VERSION ""

NS_ :

BS_:

BU_: HV500_commands HV500_controller

BO_ 3221225472 VECTOR__INDEPENDENT_SIG_MSG: 0 Vector__XXX
 SG_ NewSignal_0005 : 0|8@0+ (1,0) [0|0] "" Vector__XXX

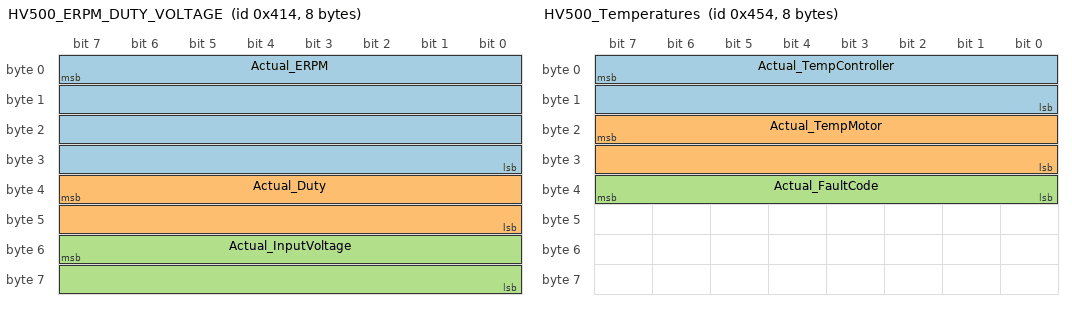
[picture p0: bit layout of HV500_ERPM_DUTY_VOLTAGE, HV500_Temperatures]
BO_ 1044 HV500_ERPM_DUTY_VOLTAGE: 8 HV500_controller
 SG_ Actual_ERPM : 7|32@0- (1,0) [-120000|120000] "ERPM"  HV500_commands
 SG_ Actual_Duty : 39|16@0- (0.1,0) [-100|100] "%"  HV500_commands
 SG_ Actual_InputVoltage : 55|16@0- (1,0) [0|1000] "V"  HV500_commands

BO_ 1076 HV500_AC_DC_current: 8 HV500_controller
 SG_ Actual_ACCurrent : 7|16@0- (0.1,0) [-850|850] "Apk"  HV500_commands
 SG_ Actual_DCCurrent : 23|16@0- (0.1,0) [-850|850] "A"  HV500_commands

BO_ 1108 HV500_Temperatures: 8 HV500_controller
 SG_ Actual_TempController : 7|16@0- (0.1,0) [-55|200] "C"  HV500_commands
 SG_ Actual_TempMotor : 23|16@0- (0.1,0) [-55|200] "C"  HV500_commands
 SG_ Actual_FaultCode : 39|8@0+ (1,0) [0|255] ""  HV500_commands

BO_ 1140 HV500_FOC: 8 HV500_controller
 SG_ Actual_FOC_id : 7|32@0- (0.01,0) [-850|850] "Apk"  HV500_commands
 SG_ Actual_FOC_iq : 39|32@0- (0.01,0) [-850|850] "Apk"  HV500_commands

BO_ 1172 HV500_MISC: 8 HV500_controller
 SG_ Actual_Throttle : 7|8@0- (1,0) [0|100] "%"  HV500_commands
 SG_ Actual_Brake : 15|8@0- (1,0) [0|100] "%"  HV500_commands
 SG_ Digital_input_1 : 16|1@0+ (1,0) [0|1] ""  HV500_commands
 SG_ Digital_input_2 : 17|1@0+ (1,0) [0|1] ""  HV500_commands
 SG_ Digital_input_3 : 18|1@0+ (1,0) [0|1] ""  HV500_commands
 SG_ Digital_input_4 : 19|1@0+ (1,0) [0|1] ""  HV500_commands
 SG_ Digital_output_1 : 20|1@0+ (1,0) [0|1] ""  HV500_commands
 SG_ Digital_output_2 : 21|1@0+ (1,0) [0|1] ""  HV500_commands
 SG_ Digital_output_3 : 22|1@0+ (1,0) [0|1] ""  HV500_commands
 SG_ Digital_output_4 : 23|1@0+ (1,0) [0|1] ""  HV500_commands
 SG_ Drive_enable : 31|8@0+ (1,0) [0|1] ""  HV500_commands
 SG_ Capacitor_temp_limit : 32|1@0+ (1,0) [0|1] ""  HV500_commands
 SG_ DC_current_limit : 33|1@0+ (1,0) [0|1] ""  HV500_commands
 SG_ Drive_enable_limit : 34|1@0+ (1,0) [0|1] ""  HV500_commands
 SG_ IGBT_accel_limit : 35|1@0+ (1,0) [0|1] ""  HV500_commands
 SG_ IGBT_temp_limit : 36|1@0+ (1,0) [0|1] ""  HV500_commands
 SG_ Input_voltage_limit : 37|1@0+ (1,0) [0|1] ""  HV500_commands
 SG_ Motor_accel_limit : 38|1@0+ (1,0) [0|1] ""  HV500_commands
 SG_ Motor_temp_limit : 39|1@0+ (1,0) [0|1] ""  HV500_commands
 SG_ RPM_min_limit : 40|1@0+ (1,0) [0|1] ""  HV500_commands
 SG_ RPM_max_limit : 41|1@0+ (1,0) [0|1] ""  HV500_commands
 SG_ Power_limit : 42|1@0+ (1,0) [0|1] ""  HV500_commands
 SG_ CAN_map_version : 63|8@0+ (0.1,0) [0|255] "Version"  HV500_commands

BO_ 388 HV500_SetDriveEnable: 2 HV500_commands
 SG_ CMD_DriveEnable : 7|8@0+ (1,0) [0|1] ""  HV500_controller

BO_ 36 HV500_SetAcCurrent: 8 HV500_commands
 SG_ CMD_TargetAcCurrent : 7|16@0- (0.1,0) [-850|850] "A"  HV500_controller

BO_ 68 HV500_SetBrakeCurrent: 8 HV500_commands
 SG_ CMD_TargetBrakeCurrent : 7|16@0- (0.1,0) [0|850] "A"  HV500_controller

BO_ 100 HV500_SetERPM: 4 HV500_commands
 SG_ CMD_TargetSpeed : 7|32@0- (1,0) [-100000|100000] "ERPM"  HV500_controller

BO_ 132 HV500_SetPosition: 2 HV500_commands
 SG_ CMD_TargetPosition : 7|16@0- (0.1,0) [0|359] "degree"  HV500_controller

BO_ 164 HV500_SetRelCurrent: 2 HV500_commands
 SG_ CMD_TargetRelativeCurrent : 7|16@0- (0.1,0) [-100|100] "%"  HV500_controller

BO_ 196 HV500_SetRelBrakeCurrent: 2 HV500_commands
 SG_ CMD_TargeRelativeBrakeCurrent : 7|16@0- (0.1,0) [0|100] "%"  HV500_controller

BO_ 260 HV500_SetMaxAcCurrent: 2 HV500_commands
 SG_ CMD_MaxAcCurrent : 7|16@0- (0.1,0) [0|850] "A"  HV500_controller

BO_ 292 HV500_SetMaxAcBrakeCurrent: 2 HV500_commands
 SG_ CMD_MaxAcBrakeCurrent : 7|16@0- (0.1,0) [-850|0] "A"  HV500_controller

BO_ 324 HV500_SetMaxDcCurrent: 2 HV500_commands
 SG_ CMD_MaxDcCurrent : 7|16@0- (0.1,0) [0|850] "A"  HV500_controller

BO_ 356 HV500_SetMaxDcBrakeCurrent: 2 HV500_commands
 SG_ CMD_MaxDcBrakeCurrent : 7|16@0- (0.1,0) [-850|0] "A"  HV500_controller

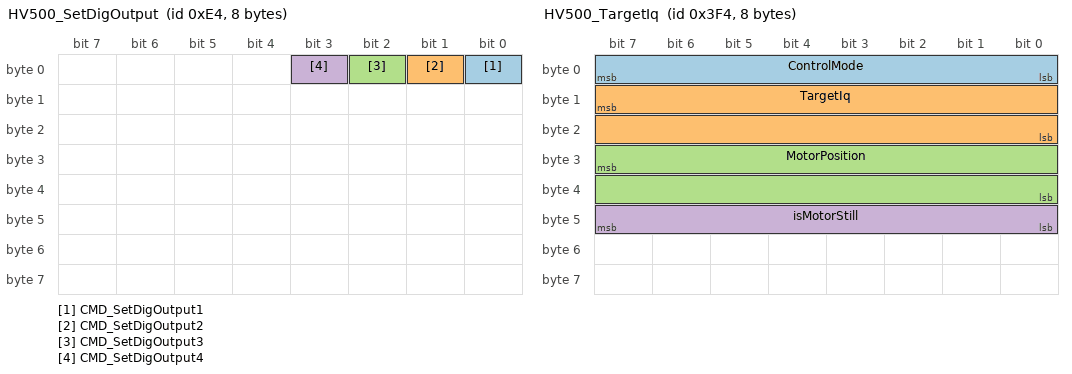
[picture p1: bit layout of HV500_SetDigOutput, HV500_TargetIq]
BO_ 228 HV500_SetDigOutput: 8 HV500_commands
 SG_ CMD_SetDigOutput1 : 0|1@0+ (1,0) [0|1] "#" Vector__XXX
 SG_ CMD_SetDigOutput2 : 1|1@0+ (1,0) [0|1] "#" Vector__XXX
 SG_ CMD_SetDigOutput3 : 2|1@0+ (1,0) [0|1] "#" Vector__XXX
 SG_ CMD_SetDigOutput4 : 3|1@0+ (1,0) [0|1] "#" Vector__XXX

BO_ 1012 HV500_TargetIq: 8 HV500_controller
 SG_ ControlMode : 7|8@0+ (1,0) [0|7] "#" Vector__XXX
 SG_ TargetIq : 15|16@0- (0.1,0) [-850|850] "Apk" Vector__XXX
 SG_ MotorPosition : 31|16@0+ (0.1,0) [0|359] "degree" Vector__XXX
 SG_ isMotorStill : 47|8@0+ (1,0) [0|1] "#" Vector__XXX

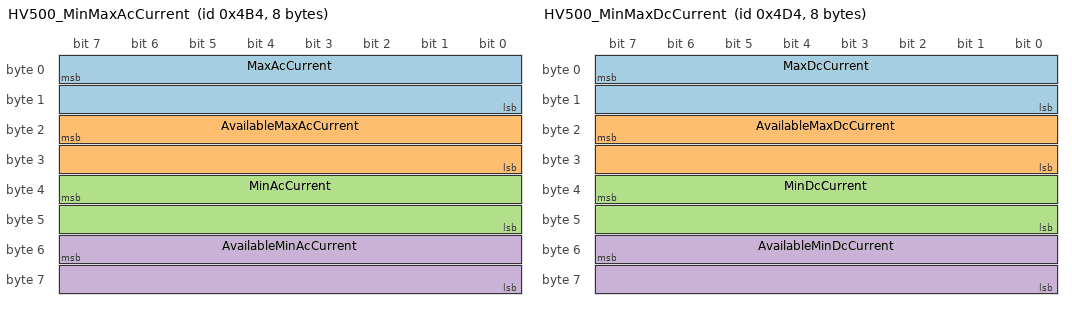
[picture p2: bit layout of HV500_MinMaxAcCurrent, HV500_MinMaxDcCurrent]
BO_ 1204 HV500_MinMaxAcCurrent: 8 HV500_controller
 SG_ MaxAcCurrent : 7|16@0- (0.1,0) [0|850] "Apk" Vector__XXX
 SG_ AvailableMaxAcCurrent : 23|16@0- (0.1,0) [0|850] "Apk" Vector__XXX
 SG_ MinAcCurrent : 39|16@0- (0.1,0) [-850|0] "Apk" Vector__XXX
 SG_ AvailableMinAcCurrent : 55|16@0- (0.1,0) [-850|0] "Apk" Vector__XXX

BO_ 1236 HV500_MinMaxDcCurrent: 8 HV500_controller
 SG_ MaxDcCurrent : 7|16@0- (0.1,0) [0|850] "Adc" Vector__XXX
 SG_ AvailableMaxDcCurrent : 23|16@0- (0.1,0) [0|850] "Adc" Vector__XXX
 SG_ MinDcCurrent : 39|16@0- (0.1,0) [-850|0] "Adc" Vector__XXX
 SG_ AvailableMinDcCurrent : 55|16@0- (0.1,0) [-850|0] "Adc" Vector__XXX

CM_ BO_ 3221225472 "This is a message for not used signals, created by Vector CANdb++ DBC OLE DB Provider.";
CM_ BO_ 1044 "Node ID: 4 (decimal)";
CM_ SG_ 1044 Actual_ERPM "Electrical RPM
Equation: ERPM = Motor RPM * number of the motor pole pairs.";
CM_ SG_ 1044 Actual_Duty "The controller duty cycle. The sign of this value will represent whether the motor is running(positive) current or regenerating (negative) current.";
CM_ SG_ 1044 Actual_InputVoltage "Input voltage is the DC voltage.";
CM_ BO_ 1076 "Node ID: 4 (decimal)";
CM_ SG_ 1076 Actual_ACCurrent "The motor current. The sign of this value represents whether the motor is running(positive) current or regenerating (negative) current.";
CM_ SG_ 1076 Actual_DCCurrent "DC Current: Current on DC side. The sign of this value represents whether the motor is running(positive) current or regenerating (negative) current.";
CM_ BO_ 1108 "Node ID: 4 (decimal)";
CM_ SG_ 1108 Actual_TempController "Temperature of the inverter semiconductors.";
CM_ SG_ 1108 Actual_TempMotor "Temperature of the motor measured by the inverter.";
CM_ SG_ 1108 Actual_FaultCode "Fault codes.";
CM_ BO_ 1140 "Node ID: 4 (decimal)";
CM_ SG_ 1140 Actual_FOC_id "FOC algorithm component Id.";
CM_ SG_ 1140 Actual_FOC_iq "FOC algorithm component Iq";
CM_ BO_ 1172 "Node ID: 4 (decimal)";
CM_ SG_ 1172 Actual_Throttle "Throttle signal derived from analog inputs or CAN2.";
CM_ SG_ 1172 Actual_Brake "Brake signal derived from analog inputs or CAN2.";
CM_ SG_ 1172 CAN_map_version "Indicates the CAN map version. For ex: 23 -> 2,3 (V2,3)";
CM_ BO_ 388 "Node ID: 4 (decimal)";
CM_ BO_ 36 "Node ID: 4 (decimal)";
CM_ SG_ 36 CMD_TargetAcCurrent "Min/Max AC current depends on configuration!";
CM_ BO_ 68 "Node ID: 4 (decimal)";
CM_ SG_ 68 CMD_TargetBrakeCurrent "Max AC brake current depends on configuration!";
CM_ BO_ 100 "Node ID: 4 (decimal)";
CM_ BO_ 132 "Node ID: 4 (decimal)";
CM_ BO_ 164 "Node ID: 4 (decimal)";
CM_ BO_ 196 "Node ID: 4 (decimal)";
CM_ BO_ 260 "Node ID: 4 (decimal)";
CM_ BO_ 292 "Node ID: 4 (decimal)";
CM_ SG_ 292 CMD_MaxAcBrakeCurrent "Minimum AC current value depends on inverter configuration!";
CM_ BO_ 324 "Node ID: 4 (decimal)";
CM_ BO_ 356 "Node ID: 4 (decimal)";
CM_ SG_ 356 CMD_MaxDcBrakeCurrent "Minimum DC current value depends on inverter configuration!";
CM_ BO_ 228 "Node ID: 4 (decimal)";
CM_ SG_ 228 CMD_SetDigOutput1 "0: OFF
1: ON";
CM_ SG_ 228 CMD_SetDigOutput2 "0: OFF
1: ON";
CM_ SG_ 228 CMD_SetDigOutput3 "0: OFF
1: ON";
CM_ SG_ 228 CMD_SetDigOutput4 "0: OFF
1: ON";
CM_ BO_ 1012 "Node ID: 4 (decimal)";
CM_ SG_ 1012 ControlMode "1: CONTROL_MODE_SPEED
2: CONTROL_MODE_CURRENT
3: CONTROL_MODE_CURRENT_BRAKE
4: CONTROL_MODE_POS
7: CONTROL_MODE_NONE
0, 5, 6: NOT USED
";
CM_ SG_ 1012 TargetIq "The value represent how much Iq current the inverter is targeted to reach. This value excludes limits. For ex. if the target Iq is 50 A and temperature limit is hit, the values keep 50 A in any case, not including the deration of the temp. limit. This is useful in multi-inverter configuration to let know the secondary inverter the target Iq. ";
CM_ SG_ 1012 MotorPosition "Motor position expressed in degrees.";
CM_ SG_ 1012 isMotorStill "Represents if the motor in still position or not. 1: still, 0: rotating";
CM_ BO_ 1204 "Node ID: 4 (decimal)";
CM_ SG_ 1204 MaxAcCurrent "Max AC current configured with the DTI CAN tool.";
CM_ SG_ 1204 AvailableMaxAcCurrent "Available max AC current. This value affected by the limitation functions (igbt temp, motortemp etc.) Defines how much current available from the configured one.";
CM_ SG_ 1204 MinAcCurrent "Min AC current configured with the DTI CAN tool.";
CM_ SG_ 1204 AvailableMinAcCurrent "Available min AC current. This value affected by the limitation functions (igbt temp, motortemp etc.) Defines how much current available from the configured one.";
CM_ BO_ 1236 "Node ID: 4 (decimal)";
CM_ SG_ 1236 MaxDcCurrent "Max DC current configured with the DTI CAN tool.";
CM_ SG_ 1236 AvailableMaxDcCurrent "Available max DC current. This value affected by the limitation functions (igbt temp, motortemp etc.) Defines how much current available from the configured one.";
CM_ SG_ 1236 MinDcCurrent "Min DC current configured with the DTI CAN tool.";
CM_ SG_ 1236 AvailableMinDcCurrent "Available min DC current. This value affected by the limitation functions (igbt temp, motortemp etc.) Defines how much current available from the configured one.";
BA_DEF_ BO_  "GenMsgSendType" ENUM  "Cyclic","IfActive";
BA_DEF_ BO_  "GenMsgCycleTime" INT 0 0;
BA_DEF_ BO_  "GenMsgBackgroundColor" STRING ;
BA_DEF_ BO_  "GenMsgForegroundColor" STRING ;
BA_DEF_DEF_  "GenMsgSendType" "Cyclic";
BA_DEF_DEF_  "GenMsgCycleTime" 0;
BA_DEF_DEF_  "GenMsgBackgroundColor" "#ffffff";
BA_DEF_DEF_  "GenMsgForegroundColor" "#000000";
BA_ "GenMsgCycleTime" BO_ 1044 100;
BA_ "GenMsgCycleTime" BO_ 1076 100;
BA_ "GenMsgCycleTime" BO_ 1108 100;
BA_ "GenMsgCycleTime" BO_ 1140 100;
BA_ "GenMsgCycleTime" BO_ 1172 100;
BA_ "GenMsgCycleTime" BO_ 388 100;
BA_ "GenMsgCycleTime" BO_ 36 100;
BA_ "GenMsgCycleTime" BO_ 68 100;
BA_ "GenMsgCycleTime" BO_ 100 100;
BA_ "GenMsgCycleTime" BO_ 132 100;
BA_ "GenMsgCycleTime" BO_ 164 100;
BA_ "GenMsgCycleTime" BO_ 196 100;
BA_ "GenMsgCycleTime" BO_ 260 100;
BA_ "GenMsgCycleTime" BO_ 292 100;
BA_ "GenMsgCycleTime" BO_ 324 100;
BA_ "GenMsgCycleTime" BO_ 356 100;
BA_ "GenMsgCycleTime" BO_ 228 100;
BA_ "GenMsgCycleTime" BO_ 1012 100;
BA_ "GenMsgCycleTime" BO_ 1204 100;
BA_ "GenMsgCycleTime" BO_ 1236 100;
VAL_ 1108 Actual_FaultCode 0 "NO_FAULT" 1 "OVERVOLTAGE_-_The_input_voltage_is_higher_than_the_set_maximum" 2 "UNDERVOLTAGE_-_The_input_voltage_is_lower_than_the_set_minimum" 3 "DRV_ERROR_-_Transistor_or_transistor_drive_error" 4 "ABSOLUTE_MAX_OVERCURRENT_-_The_AC_current_is_higher_than_the_set_absolute_maximum_current" 5 "CONTROLLER_OVERTEMPERATURE_-_The_controller_temperature_is_higher_than_the_set_maximum" 6 "MOTOR_OVERTEMPERATURE_-_The_motor_temperature_is_higher_than_the_set_maximum" 7 "SENSOR_WIRE_FAULT_-_Something_went_wrong_with_the_sensor_differential_signals" 8 "SENSOR_GENERAL_FAULT_-_An_error_occurred_while_processing_the_sensor_signals" 9 "CAN_COMMAND_ERROR_-_CAN_message_received_contains_parameter_out_of_boundaries" 10 "ANALOG_INPUT_ERROR_–_Redundant_output_out_of_range" ;
VAL_ 1172 Digital_input_1 0 "Input_1_disabled" 1 "Input_1_enabled" ;
VAL_ 1172 Digital_input_2 0 "Input_2_enabled" 1 "Input_2_enabled" ;
VAL_ 1172 Digital_input_3 0 "Input_3_disabled" 1 "Input_3_enabled" ;
VAL_ 1172 Digital_input_4 0 "Input_4_disabled" 1 "Input_4_enabled" ;
VAL_ 1172 Digital_output_1 0 "Output_1_disabled" 1 "Output_1_enabled" ;
VAL_ 1172 Digital_output_2 0 "Output_2_disabled" 1 "Output_2_enabled" ;
VAL_ 1172 Digital_output_3 0 "Output_3_disabled" 1 "Output_3_enabled" ;
VAL_ 1172 Digital_output_4 0 "Output_4_disabled" 1 "Output_4_enabled" ;
VAL_ 1172 Drive_enable 0 "Drive_disabled" 1 "Drive_enabled" ;
VAL_ 1172 Capacitor_temp_limit 0 "Capacitor_temperature_limit_inactive" 1 "Capacitor_temperature_limit_active" ;
VAL_ 1172 DC_current_limit 1 "DC_current_limit_active" 0 "DC_current_limit_inactive" ;
VAL_ 1172 Drive_enable_limit 0 "Drive_enable_limit_inactive" 1 "Drive_enable_limit_active" ;
VAL_ 1172 IGBT_accel_limit 0 "IGBT_acceleration_temperature_limit_inactive" 1 "IGBT_acceleration_temperature_limit_inactive" ;
VAL_ 1172 IGBT_temp_limit 0 "IGBT_temperature_limit_inactive" 1 "IGBT_temperature_limit_active" ;
VAL_ 1172 Input_voltage_limit 0 "Input_voltage_limit_inactive" 1 "Input_voltage_limit_active" ;
VAL_ 1172 Motor_accel_limit 0 "Motor_acceleration_temperature_limit_inactive" 1 "Motor_acceleration_temperature_limit_active" ;
VAL_ 1172 Motor_temp_limit 0 "Motor_temperature_limit_inactive" 1 "Motor_temperature_limit_active" ;
VAL_ 1172 RPM_min_limit 0 "RPM_minimum_limit_inactive" 1 "RPM_minimum_limit_active" ;
VAL_ 1172 RPM_max_limit 0 "RPM_maximum_limit_inactive" 1 "RPM_maximum_limit_active" ;
VAL_ 1172 Power_limit 0 "Power_limit_inactive" 1 "Power_limit_active" ;
VAL_ 388 CMD_DriveEnable 1 "Drive allowed" 0 "Drive_not_allowed" ;
